# LM3S9D92 register map
File version: 7944
Registers are 32-bit, read-write, no defined reset value unless marked. A register's access mark holds for its fields unless they carry their own. Offsets are from the block's base; [hi:lo] are bit positions; {n}, {i} and the like mark numbered series.

## MAC — Register map for MAC peripheral
Base 0x40048000; register names take the prefix MAC
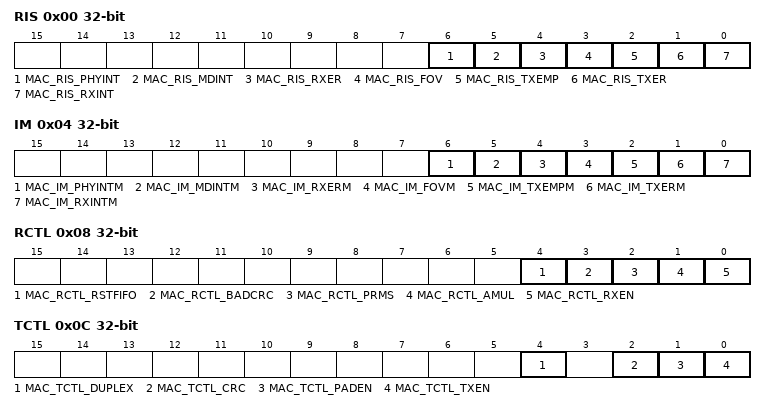
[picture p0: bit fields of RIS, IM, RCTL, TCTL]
0x00 RIS — Ethernet MAC Raw Interrupt Status/Acknowledge
  [6] MAC_RIS_PHYINT — PHY Interrupt
  [5] MAC_RIS_MDINT — MII Transaction Complete
  [4] MAC_RIS_RXER — Receive Error
  [3] MAC_RIS_FOV — FIFO Overrun
  [2] MAC_RIS_TXEMP — Transmit FIFO Empty
  [1] MAC_RIS_TXER — Transmit Error
  [0] MAC_RIS_RXINT — Packet Received
0x04 IM — Ethernet MAC Interrupt Mask
  [6] MAC_IM_PHYINTM — Mask PHY Interrupt
  [5] MAC_IM_MDINTM — Mask MII Transaction Complete
  [4] MAC_IM_RXERM — Mask Receive Error
  [3] MAC_IM_FOVM — Mask FIFO Overrun
  [2] MAC_IM_TXEMPM — Mask Transmit FIFO Empty
  [1] MAC_IM_TXERM — Mask Transmit Error
  [0] MAC_IM_RXINTM — Mask Packet Received
0x08 RCTL — Ethernet MAC Receive Control
  [4] MAC_RCTL_RSTFIFO — Clear Receive FIFO
  [3] MAC_RCTL_BADCRC — Enable Reject Bad CRC
  [2] MAC_RCTL_PRMS — Enable Promiscuous Mode
  [1] MAC_RCTL_AMUL — Enable Multicast Frames
  [0] MAC_RCTL_RXEN — Enable Receiver
0x0C TCTL — Ethernet MAC Transmit Control
  [4] MAC_TCTL_DUPLEX — Enable Duplex Mode
  [2] MAC_TCTL_CRC — Enable CRC Generation
  [1] MAC_TCTL_PADEN — Enable Packet Padding
  [0] MAC_TCTL_TXEN — Enable Transmitter
0x10 DATA — Ethernet MAC Data
  [31:0] MAC_DATA_RXDATA — Receive FIFO Data
0x10 DATA (MAC_ALT view) — Ethernet MAC Data
  [31:0] MAC_DATA_TXDATA — Transmit FIFO Data
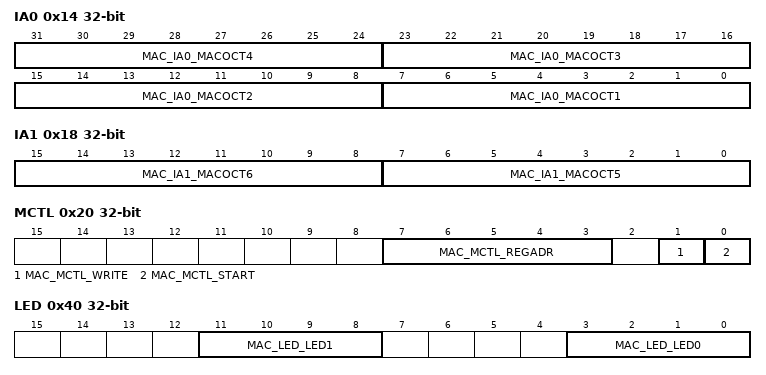
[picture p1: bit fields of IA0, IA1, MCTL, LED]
0x14 IA0 — Ethernet MAC Individual Address 0
  [8n-1:8n-8] MAC_IA0_MACOCT{n} (n=1..4) — MAC Address Octet {n}
0x18 IA1 — Ethernet MAC Individual Address 1
  [15:8] MAC_IA1_MACOCT6 — MAC Address Octet 6
  [7:0] MAC_IA1_MACOCT5 — MAC Address Octet 5
0x1C THR — Ethernet MAC Threshold
  [5:0] MAC_THR_THRESH — Threshold Value
0x20 MCTL — Ethernet MAC Management Control
  [7:3] MAC_MCTL_REGADR — MII Register Address
  [1] MAC_MCTL_WRITE — MII Register Transaction Type
  [0] MAC_MCTL_START — MII Register Transaction Enable
0x24 MDV — Ethernet MAC Management Divider
  [7:0] MAC_MDV_DIV — Clock Divider
0x2C MTXD — Ethernet MAC Management Transmit Data
  [15:0] MAC_MTXD_MDTX — MII Register Transmit Data
0x30 MRXD — Ethernet MAC Management Receive Data
  [15:0] MAC_MRXD_MDRX — MII Register Receive Data
0x34 NP — Ethernet MAC Number of Packets
  [5:0] MAC_NP_NPR — Number of Packets in Receive FIFO
0x38 TR — Ethernet MAC Transmission Request
  [0] MAC_TR_NEWTX — New Transmission
0x3C TS — Ethernet MAC Timer Support
  [0] MAC_TS_TSEN — Time Stamp Enable
0x40 LED — Ethernet MAC LED Encoding
  [11:8] MAC_LED_LED1 — LED1 Source
    0=MAC_LED_LED1_LINK (Link OK); 1=MAC_LED_LED1_RXTX (RX or TX Activity (Default LED1)); 5=100BASE-TX mode; 6=10BASE-T mode; 7=MAC_LED_LED1_DUPLEX (Full-Duplex); 8=MAC_LED_LED1_LINKACT (Link OK & Blink=RX or TX Activity)
  [3:0] MAC_LED_LED0 — LED0 Source
    0=MAC_LED_LED0_LINK (Link OK (Default LED0)); 1=MAC_LED_LED0_RXTX (RX or TX Activity); 5=100BASE-TX mode; 6=10BASE-T mode; 7=MAC_LED_LED0_DUPLEX (Full-Duplex); 8=MAC_LED_LED0_LINKACT (Link OK & Blink=RX or TX Activity)
0x44 MDIX — Ethernet PHY MDIX
  [0] MAC_MDIX_EN — MDI/MDI-X Enable

## I2S0 — Register map for I2S0 peripheral
Base 0x40054000; register names take the prefix I2S0
0x00 TXFIFO wo — I2S Transmit FIFO Data
  [31:0] I2S_TXFIFO — TX Data
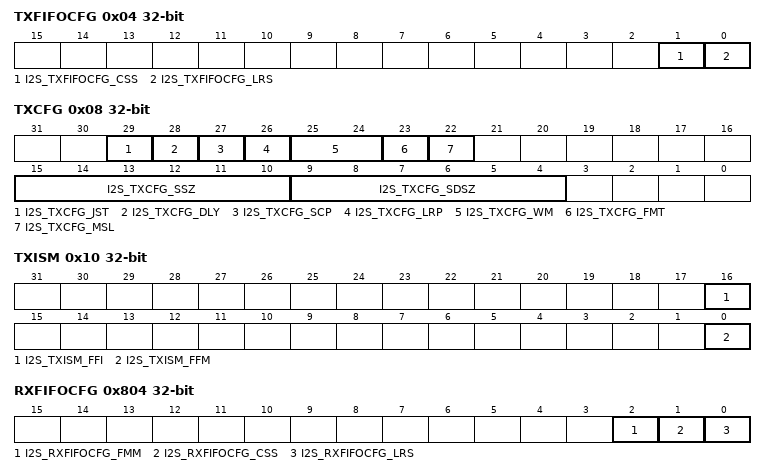
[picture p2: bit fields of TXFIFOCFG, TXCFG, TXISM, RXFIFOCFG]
0x04 TXFIFOCFG — I2S Transmit FIFO Configuration
  [1] I2S_TXFIFOCFG_CSS — Compact Stereo Sample Size
  [0] I2S_TXFIFOCFG_LRS — Left-Right Sample Indicator
0x08 TXCFG — I2S Transmit Module Configuration
  [29] I2S_TXCFG_JST — Justification of Output Data
  [28] I2S_TXCFG_DLY — Data Delay
  [27] I2S_TXCFG_SCP — SCLK Polarity
  [26] I2S_TXCFG_LRP — Left/Right Clock Polarity
  [25:24] I2S_TXCFG_WM — Write Mode
    0=I2S_TXCFG_WM_DUAL (Stereo mode); 1=I2S_TXCFG_WM_COMPACT (Compact Stereo mode); 2=I2S_TXCFG_WM_MONO (Mono mode)
  [23] I2S_TXCFG_FMT — FIFO Empty
  [22] I2S_TXCFG_MSL — SCLK Master/Slave
  [15:10] I2S_TXCFG_SSZ — Sample Size
  [9:4] I2S_TXCFG_SDSZ — System Data Size
0x0C TXLIMIT — I2S Transmit FIFO Limit
  [4:0] I2S_TXLIMIT_LIMIT — FIFO Limit
0x10 TXISM — I2S Transmit Interrupt Status and Mask
  [16] I2S_TXISM_FFI — Transmit FIFO Service Request Interrupt
  [0] I2S_TXISM_FFM — FIFO Interrupt Mask
0x18 TXLEV — I2S Transmit FIFO Level
  [4:0] I2S_TXLEV_LEVEL — Number of Audio Samples
0x800 RXFIFO — I2S Receive FIFO Data
  [31:0] I2S_RXFIFO — RX Data
0x804 RXFIFOCFG — I2S Receive FIFO Configuration
  [2] I2S_RXFIFOCFG_FMM — FIFO Mono Mode
  [1] I2S_RXFIFOCFG_CSS — Compact Stereo Sample Size
  [0] I2S_RXFIFOCFG_LRS — Left-Right Sample Indicator
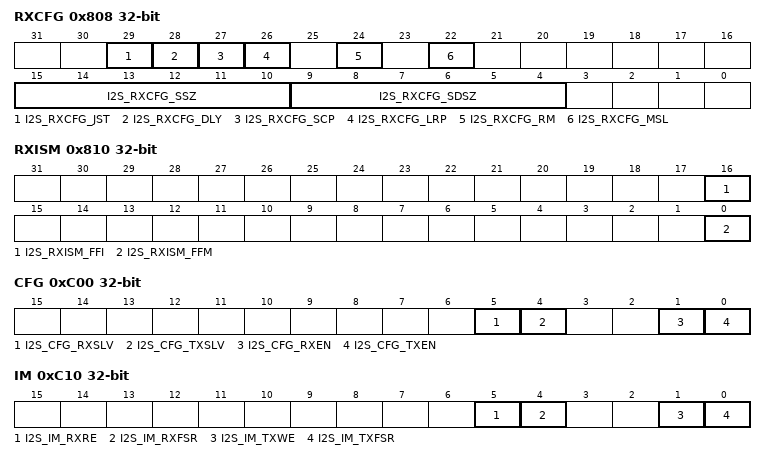
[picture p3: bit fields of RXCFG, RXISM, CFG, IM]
0x808 RXCFG — I2S Receive Module Configuration
  [29] I2S_RXCFG_JST — Justification of Input Data
  [28] I2S_RXCFG_DLY — Data Delay
  [27] I2S_RXCFG_SCP — SCLK Polarity
  [26] I2S_RXCFG_LRP — Left/Right Clock Polarity
  [24] I2S_RXCFG_RM — Read Mode
  [22] I2S_RXCFG_MSL — SCLK Master/Slave
  [15:10] I2S_RXCFG_SSZ — Sample Size
  [9:4] I2S_RXCFG_SDSZ — System Data Size
0x80C RXLIMIT — I2S Receive FIFO Limit
  [4:0] I2S_RXLIMIT_LIMIT — FIFO Limit
0x810 RXISM — I2S Receive Interrupt Status and Mask
  [16] I2S_RXISM_FFI — Receive FIFO Service Request Interrupt
  [0] I2S_RXISM_FFM — FIFO Interrupt Mask
0x818 RXLEV — I2S Receive FIFO Level
  [4:0] I2S_RXLEV_LEVEL — Number of Audio Samples
0xC00 CFG — I2S Module Configuration
  [5] I2S_CFG_RXSLV — Use External I2S0RXMCLK
  [4] I2S_CFG_TXSLV — Use External I2S0TXMCLK
  [1] I2S_CFG_RXEN — Serial Receive Engine Enable
  [0] I2S_CFG_TXEN — Serial Transmit Engine Enable
0xC10 IM — I2S Interrupt Mask
  [5] I2S_IM_RXRE — Receive FIFO Read Error
  [4] I2S_IM_RXFSR — Receive FIFO Service Request
  [1] I2S_IM_TXWE — Transmit FIFO Write Error
  [0] I2S_IM_TXFSR — Transmit FIFO Service Request
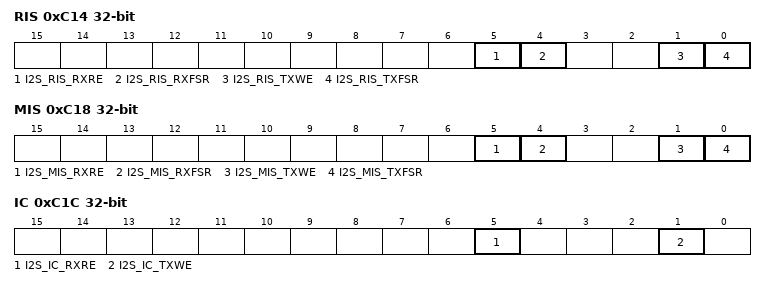
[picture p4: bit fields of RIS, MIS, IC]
0xC14 RIS — I2S Raw Interrupt Status
  [5] I2S_RIS_RXRE — Receive FIFO Read Error
  [4] I2S_RIS_RXFSR — Receive FIFO Service Request
  [1] I2S_RIS_TXWE — Transmit FIFO Write Error
  [0] I2S_RIS_TXFSR — Transmit FIFO Service Request
0xC18 MIS — I2S Masked Interrupt Status
  [5] I2S_MIS_RXRE — Receive FIFO Read Error
  [4] I2S_MIS_RXFSR — Receive FIFO Service Request
  [1] I2S_MIS_TXWE — Transmit FIFO Write Error
  [0] I2S_MIS_TXFSR — Transmit FIFO Service Request
0xC1C IC wo — I2S Interrupt Clear
  [5] I2S_IC_RXRE — Receive FIFO Read Error
  [1] I2S_IC_TXWE — Transmit FIFO Write Error
